AUTOSAR XML
package /BbwComponents
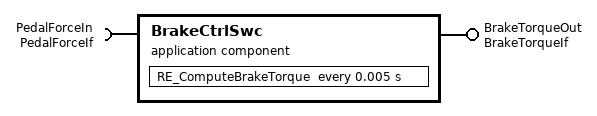
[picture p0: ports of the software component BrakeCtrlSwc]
  application sw component type BrakeCtrlSwc
    require port PedalForceIn: required-interface=PedalForceIf
    provide port BrakeTorqueOut: provided-interface=BrakeTorqueIf
    behavior BrakeCtrl_IB
      runnable RE_ComputeBrakeTorque: execution-time-wcet=0.0018
      timing event TE_BrakeCtrl_5ms: start-on-event=RE_ComputeBrakeTorque, period=0.005
